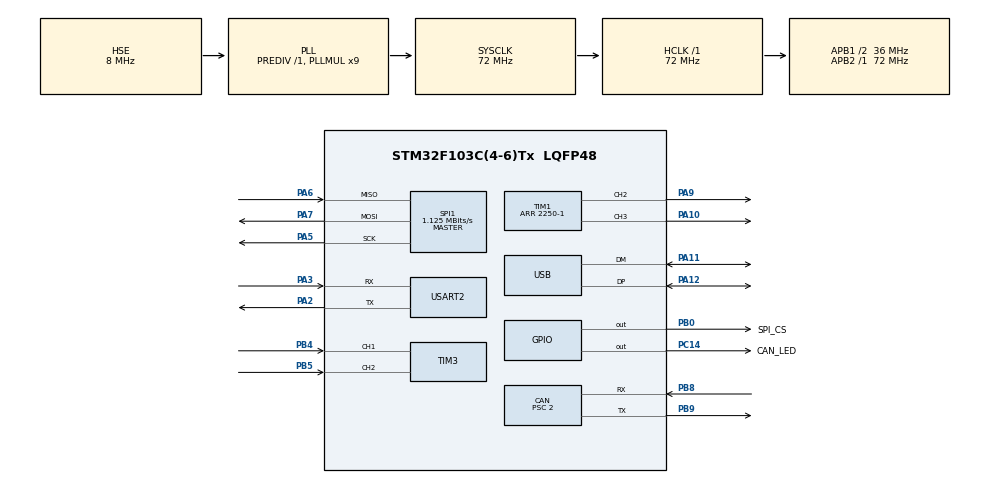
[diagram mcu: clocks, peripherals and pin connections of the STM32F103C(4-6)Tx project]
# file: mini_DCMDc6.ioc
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CAN.ABOM=ENABLE
CAN.BS1=CAN_BS1_14TQ
CAN.BS2=CAN_BS2_3TQ
CAN.CalculateBaudRate=1000000
CAN.CalculateTimeBit=1000
CAN.CalculateTimeQuantum=55.55555555555556
CAN.NART=ENABLE
CAN.Prescaler=2
CAN.SJW=CAN_SJW_1TQ
Mcu.Family=STM32F1
Mcu.Name=STM32F103C(4-6)Tx
Mcu.Package=LQFP48
NVIC.PriorityGroup=NVIC_PRIORITYGROUP_4
PA10.Signal=S_TIM1_CH3
PA11.Mode=Device
PA11.Signal=USB_DM
PA12.Mode=Device
PA12.Signal=USB_DP
PA13.Mode=Serial_Wire
PA13.Signal=SYS_JTMS-SWDIO
PA14.Mode=Serial_Wire
PA14.Signal=SYS_JTCK-SWCLK
PA2.Mode=Asynchronous
PA2.Signal=USART2_TX
PA3.Mode=Asynchronous
PA3.Signal=USART2_RX
PA5.Mode=Full_Duplex_Master
PA5.Signal=SPI1_SCK
PA6.Mode=Full_Duplex_Master
PA6.Signal=SPI1_MISO
PA7.Mode=Full_Duplex_Master
PA7.Signal=SPI1_MOSI
PA9.Signal=S_TIM1_CH2
PB0.GPIO_Label=SPI_CS
PB0.Signal=GPIO_Output
PB4.Signal=S_TIM3_CH1
PB5.Signal=S_TIM3_CH2
PB8.Mode=CAN_Activate
PB8.Signal=CAN_RX
PB9.Mode=CAN_Activate
PB9.Signal=CAN_TX
PC14-OSC32_IN.GPIO_Label=CAN_LED
PC14-OSC32_IN.Signal=GPIO_Output
PD0-OSC_IN.Mode=HSE-External-Oscillator
PD0-OSC_IN.Signal=RCC_OSC_IN
PD1-OSC_OUT.Mode=HSE-External-Oscillator
PD1-OSC_OUT.Signal=RCC_OSC_OUT
ProjectManager.HeapSize=0x200
ProjectManager.StackSize=0x400
ProjectManager.TargetToolchain=STM32CubeIDE
RCC.AHBFreq_Value=72000000
RCC.APB1CLKDivider=RCC_HCLK_DIV2
RCC.APB1Freq_Value=36000000
RCC.APB1TimFreq_Value=72000000
RCC.APB2Freq_Value=72000000
RCC.APB2TimFreq_Value=72000000
RCC.HCLKFreq_Value=72000000
RCC.PLLMUL=RCC_PLL_MUL9
RCC.PLLSourceVirtual=RCC_PLLSOURCE_HSE
RCC.SYSCLKFreq_VALUE=72000000
RCC.SYSCLKSource=RCC_SYSCLKSOURCE_PLLCLK
RCC.USBFreq_Value=48000000
RCC.USBPrescaler=RCC_USBCLKSOURCE_PLL_DIV1_5
SH.S_TIM1_CH2.0=TIM1_CH2,PWM Generation2 CH2
SH.S_TIM1_CH3.0=TIM1_CH3,PWM Generation3 CH3
SH.S_TIM3_CH1.0=TIM3_CH1,Encoder_Interface
SH.S_TIM3_CH2.0=TIM3_CH2,Encoder_Interface
SPI1.BaudRatePrescaler=SPI_BAUDRATEPRESCALER_64
SPI1.CLKPhase=SPI_PHASE_1EDGE
SPI1.CLKPolarity=SPI_POLARITY_HIGH
SPI1.CalculateBaudRate=1.125 MBits/s
SPI1.Direction=SPI_DIRECTION_2LINES
SPI1.Mode=SPI_MODE_MASTER
SPI1.VirtualType=VM_MASTER
TIM1.Channel-PWM\ Generation2\ CH2=TIM_CHANNEL_2
TIM1.Channel-PWM\ Generation3\ CH3=TIM_CHANNEL_3
TIM1.ClockDivision=TIM_CLOCKDIVISION_DIV4
TIM1.CounterMode=TIM_COUNTERMODE_CENTERALIGNED1
TIM1.Period=2250-1
TIM1.Pulse-PWM\ Generation2\ CH2=300
TIM1.Pulse-PWM\ Generation3\ CH3=1
USART2.VirtualMode=VM_ASYNC
VP_TIM1_VS_ClockSourceINT.Mode=Internal
board=custom

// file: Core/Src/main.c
/* USER CODE BEGIN Header */
/**
  ******************************************************************************
  * @file           : main.c
  * @brief          : Main program body
  ******************************************************************************
  * @attention
  *
  * Copyright (c) 2023 STMicroelectronics.
  * All rights reserved.
  *
  * This software is licensed under terms that can be found in the LICENSE file
  * in the root directory of this software component.
  * If no LICENSE file comes with this software, it is provided AS-IS.
  *
  ******************************************************************************
  */
/* USER CODE END Header */
#include "main.h"

CAN_HandleTypeDef hcan;

SPI_HandleTypeDef hspi1;

TIM_HandleTypeDef htim1;
TIM_HandleTypeDef htim3;

UART_HandleTypeDef huart2;

PCD_HandleTypeDef hpcd_USB_FS;

void SystemClock_Config(void);
static void MX_GPIO_Init(void);
static void MX_CAN_Init(void);
static void MX_USB_PCD_Init(void);
static void MX_TIM3_Init(void);
static void MX_TIM1_Init(void);
static void MX_USART2_UART_Init(void);
static void MX_SPI1_Init(void);

int main(void)
{

  /* MCU Configuration--------------------------------------------------------*/

  /* Reset of all peripherals, Initializes the Flash interface and the Systick. */
  HAL_Init();

  /* Configure the system clock */
  SystemClock_Config();

  /* Initialize all configured peripherals */
  MX_GPIO_Init();
  MX_CAN_Init();
  MX_USB_PCD_Init();
  MX_TIM3_Init();
  MX_TIM1_Init();
  MX_USART2_UART_Init();
  MX_SPI1_Init();
  /* USER CODE BEGIN 2 */
main_cpp();
  /* USER CODE END 2 */

  /* Infinite loop */
  /* USER CODE BEGIN WHILE */

//  while (1)
//  {
    /* USER CODE END WHILE */

    /* USER CODE BEGIN 3 */
//  }
  /* USER CODE END 3 */
}

void SystemClock_Config(void)
{
  RCC_OscInitTypeDef RCC_OscInitStruct = {0};
  RCC_ClkInitTypeDef RCC_ClkInitStruct = {0};
  RCC_PeriphCLKInitTypeDef PeriphClkInit = {0};

  /** Initializes the RCC Oscillators according to the specified parameters
  * in the RCC_OscInitTypeDef structure.
  */
  RCC_OscInitStruct.OscillatorType = RCC_OSCILLATORTYPE_HSE;
  RCC_OscInitStruct.HSEState = RCC_HSE_ON;
  RCC_OscInitStruct.HSEPredivValue = RCC_HSE_PREDIV_DIV1;
  RCC_OscInitStruct.HSIState = RCC_HSI_ON;
  RCC_OscInitStruct.PLL.PLLState = RCC_PLL_ON;
  RCC_OscInitStruct.PLL.PLLSource = RCC_PLLSOURCE_HSE;
  RCC_OscInitStruct.PLL.PLLMUL = RCC_PLL_MUL9;
  if (HAL_RCC_OscConfig(&RCC_OscInitStruct) != HAL_OK)
  {
    Error_Handler();
  }

  /** Initializes the CPU, AHB and APB buses clocks
  */
  RCC_ClkInitStruct.ClockType = RCC_CLOCKTYPE_HCLK|RCC_CLOCKTYPE_SYSCLK
                              |RCC_CLOCKTYPE_PCLK1|RCC_CLOCKTYPE_PCLK2;
  RCC_ClkInitStruct.SYSCLKSource = RCC_SYSCLKSOURCE_PLLCLK;
  RCC_ClkInitStruct.AHBCLKDivider = RCC_SYSCLK_DIV1;
  RCC_ClkInitStruct.APB1CLKDivider = RCC_HCLK_DIV2;
  RCC_ClkInitStruct.APB2CLKDivider = RCC_HCLK_DIV1;

  if (HAL_RCC_ClockConfig(&RCC_ClkInitStruct, FLASH_LATENCY_2) != HAL_OK)
  {
    Error_Handler();
  }
  PeriphClkInit.PeriphClockSelection = RCC_PERIPHCLK_USB;
  PeriphClkInit.UsbClockSelection = RCC_USBCLKSOURCE_PLL_DIV1_5;
  if (HAL_RCCEx_PeriphCLKConfig(&PeriphClkInit) != HAL_OK)
  {
    Error_Handler();
  }
}

static void MX_CAN_Init(void)
{

  hcan.Instance = CAN1;
  hcan.Init.Prescaler = 2;
  hcan.Init.Mode = CAN_MODE_NORMAL;
  hcan.Init.SyncJumpWidth = CAN_SJW_1TQ;
  hcan.Init.TimeSeg1 = CAN_BS1_14TQ;
  hcan.Init.TimeSeg2 = CAN_BS2_3TQ;
  hcan.Init.TimeTriggeredMode = DISABLE;
  hcan.Init.AutoBusOff = ENABLE;
  hcan.Init.AutoWakeUp = DISABLE;
  hcan.Init.AutoRetransmission = ENABLE;
  hcan.Init.ReceiveFifoLocked = DISABLE;
  hcan.Init.TransmitFifoPriority = DISABLE;
  if (HAL_CAN_Init(&hcan) != HAL_OK)
  {
    Error_Handler();
  }

}

static void MX_SPI1_Init(void)
{

  /* SPI1 parameter configuration*/
  hspi1.Instance = SPI1;
  hspi1.Init.Mode = SPI_MODE_MASTER;
  hspi1.Init.Direction = SPI_DIRECTION_2LINES;
  hspi1.Init.DataSize = SPI_DATASIZE_8BIT;
  hspi1.Init.CLKPolarity = SPI_POLARITY_HIGH;
  hspi1.Init.CLKPhase = SPI_PHASE_1EDGE;
  hspi1.Init.NSS = SPI_NSS_SOFT;
  hspi1.Init.BaudRatePrescaler = SPI_BAUDRATEPRESCALER_64;
  hspi1.Init.FirstBit = SPI_FIRSTBIT_MSB;
  hspi1.Init.TIMode = SPI_TIMODE_DISABLE;
  hspi1.Init.CRCCalculation = SPI_CRCCALCULATION_DISABLE;
  hspi1.Init.CRCPolynomial = 10;
  if (HAL_SPI_Init(&hspi1) != HAL_OK)
  {
    Error_Handler();
  }

}

static void MX_TIM1_Init(void)
{

  TIM_ClockConfigTypeDef sClockSourceConfig = {0};
  TIM_MasterConfigTypeDef sMasterConfig = {0};
  TIM_OC_InitTypeDef sConfigOC = {0};
  TIM_BreakDeadTimeConfigTypeDef sBreakDeadTimeConfig = {0};

  htim1.Instance = TIM1;
  htim1.Init.Prescaler = 0;
  htim1.Init.CounterMode = TIM_COUNTERMODE_CENTERALIGNED1;
  htim1.Init.Period = 2250-1;
  htim1.Init.ClockDivision = TIM_CLOCKDIVISION_DIV4;
  htim1.Init.RepetitionCounter = 0;
  htim1.Init.AutoReloadPreload = TIM_AUTORELOAD_PRELOAD_DISABLE;
  if (HAL_TIM_Base_Init(&htim1) != HAL_OK)
  {
    Error_Handler();
  }
  sClockSourceConfig.ClockSource = TIM_CLOCKSOURCE_INTERNAL;
  if (HAL_TIM_ConfigClockSource(&htim1, &sClockSourceConfig) != HAL_OK)
  {
    Error_Handler();
  }
  if (HAL_TIM_PWM_Init(&htim1) != HAL_OK)
  {
    Error_Handler();
  }
  sMasterConfig.MasterOutputTrigger = TIM_TRGO_RESET;
  sMasterConfig.MasterSlaveMode = TIM_MASTERSLAVEMODE_DISABLE;
  if (HAL_TIMEx_MasterConfigSynchronization(&htim1, &sMasterConfig) != HAL_OK)
  {
    Error_Handler();
  }
  sConfigOC.OCMode = TIM_OCMODE_PWM1;
  sConfigOC.Pulse = 300;
  sConfigOC.OCPolarity = TIM_OCPOLARITY_HIGH;
  sConfigOC.OCNPolarity = TIM_OCNPOLARITY_HIGH;
  sConfigOC.OCFastMode = TIM_OCFAST_DISABLE;
  sConfigOC.OCIdleState = TIM_OCIDLESTATE_RESET;
  sConfigOC.OCNIdleState = TIM_OCNIDLESTATE_RESET;
  if (HAL_TIM_PWM_ConfigChannel(&htim1, &sConfigOC, TIM_CHANNEL_2) != HAL_OK)
  {
    Error_Handler();
  }
  sConfigOC.Pulse = 1;
  if (HAL_TIM_PWM_ConfigChannel(&htim1, &sConfigOC, TIM_CHANNEL_3) != HAL_OK)
  {
    Error_Handler();
  }
  sBreakDeadTimeConfig.OffStateRunMode = TIM_OSSR_DISABLE;
  sBreakDeadTimeConfig.OffStateIDLEMode = TIM_OSSI_DISABLE;
  sBreakDeadTimeConfig.LockLevel = TIM_LOCKLEVEL_OFF;
  sBreakDeadTimeConfig.DeadTime = 0;
  sBreakDeadTimeConfig.BreakState = TIM_BREAK_DISABLE;
  sBreakDeadTimeConfig.BreakPolarity = TIM_BREAKPOLARITY_HIGH;
  sBreakDeadTimeConfig.AutomaticOutput = TIM_AUTOMATICOUTPUT_DISABLE;
  if (HAL_TIMEx_ConfigBreakDeadTime(&htim1, &sBreakDeadTimeConfig) != HAL_OK)
  {
    Error_Handler();
  }
  HAL_TIM_MspPostInit(&htim1);

}

static void MX_TIM3_Init(void)
{

  TIM_Encoder_InitTypeDef sConfig = {0};
  TIM_MasterConfigTypeDef sMasterConfig = {0};

  htim3.Instance = TIM3;
  htim3.Init.Prescaler = 0;
  htim3.Init.CounterMode = TIM_COUNTERMODE_UP;
  htim3.Init.Period = 65535;
  htim3.Init.ClockDivision = TIM_CLOCKDIVISION_DIV1;
  htim3.Init.AutoReloadPreload = TIM_AUTORELOAD_PRELOAD_DISABLE;
  sConfig.EncoderMode = TIM_ENCODERMODE_TI1;
  sConfig.IC1Polarity = TIM_ICPOLARITY_RISING;
  sConfig.IC1Selection = TIM_ICSELECTION_DIRECTTI;
  sConfig.IC1Prescaler = TIM_ICPSC_DIV1;
  sConfig.IC1Filter = 0;
  sConfig.IC2Polarity = TIM_ICPOLARITY_RISING;
  sConfig.IC2Selection = TIM_ICSELECTION_DIRECTTI;
  sConfig.IC2Prescaler = TIM_ICPSC_DIV1;
  sConfig.IC2Filter = 0;
  if (HAL_TIM_Encoder_Init(&htim3, &sConfig) != HAL_OK)
  {
    Error_Handler();
  }
  sMasterConfig.MasterOutputTrigger = TIM_TRGO_RESET;
  sMasterConfig.MasterSlaveMode = TIM_MASTERSLAVEMODE_DISABLE;
  if (HAL_TIMEx_MasterConfigSynchronization(&htim3, &sMasterConfig) != HAL_OK)
  {
    Error_Handler();
  }

}

static void MX_USART2_UART_Init(void)
{

  huart2.Instance = USART2;
  huart2.Init.BaudRate = 115200;
  huart2.Init.WordLength = UART_WORDLENGTH_8B;
  huart2.Init.StopBits = UART_STOPBITS_1;
  huart2.Init.Parity = UART_PARITY_NONE;
  huart2.Init.Mode = UART_MODE_TX_RX;
  huart2.Init.HwFlowCtl = UART_HWCONTROL_NONE;
  huart2.Init.OverSampling = UART_OVERSAMPLING_16;
  if (HAL_UART_Init(&huart2) != HAL_OK)
  {
    Error_Handler();
  }

}

static void MX_USB_PCD_Init(void)
{

  hpcd_USB_FS.Instance = USB;
  hpcd_USB_FS.Init.dev_endpoints = 8;
  hpcd_USB_FS.Init.speed = PCD_SPEED_FULL;
  hpcd_USB_FS.Init.low_power_enable = DISABLE;
  hpcd_USB_FS.Init.lpm_enable = DISABLE;
  hpcd_USB_FS.Init.battery_charging_enable = DISABLE;
  if (HAL_PCD_Init(&hpcd_USB_FS) != HAL_OK)
  {
    Error_Handler();
  }

}

static void MX_GPIO_Init(void)
{
  GPIO_InitTypeDef GPIO_InitStruct = {0};

  /* GPIO Ports Clock Enable */
  __HAL_RCC_GPIOC_CLK_ENABLE();
  __HAL_RCC_GPIOD_CLK_ENABLE();
  __HAL_RCC_GPIOA_CLK_ENABLE();
  __HAL_RCC_GPIOB_CLK_ENABLE();

  /*Configure GPIO pin Output Level */
  HAL_GPIO_WritePin(CAN_LED_GPIO_Port, CAN_LED_Pin, GPIO_PIN_RESET);

  /*Configure GPIO pin Output Level */
  HAL_GPIO_WritePin(SPI_CS_GPIO_Port, SPI_CS_Pin, GPIO_PIN_RESET);

  /*Configure GPIO pin : CAN_LED_Pin */
  GPIO_InitStruct.Pin = CAN_LED_Pin;
  GPIO_InitStruct.Mode = GPIO_MODE_OUTPUT_PP;
  GPIO_InitStruct.Pull = GPIO_NOPULL;
  GPIO_InitStruct.Speed = GPIO_SPEED_FREQ_LOW;
  HAL_GPIO_Init(CAN_LED_GPIO_Port, &GPIO_InitStruct);

  /*Configure GPIO pin : SPI_CS_Pin */
  GPIO_InitStruct.Pin = SPI_CS_Pin;
  GPIO_InitStruct.Mode = GPIO_MODE_OUTPUT_PP;
  GPIO_InitStruct.Pull = GPIO_NOPULL;
  GPIO_InitStruct.Speed = GPIO_SPEED_FREQ_LOW;
  HAL_GPIO_Init(SPI_CS_GPIO_Port, &GPIO_InitStruct);

}

void Error_Handler(void)
{
  __disable_irq();
  while (1)
  {
  }
}
